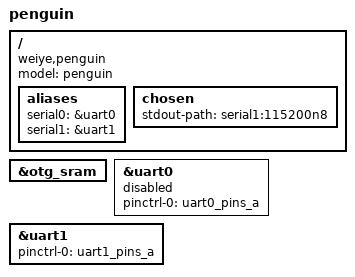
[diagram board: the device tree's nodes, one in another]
// SPDX-License-Identifier: (GPL-2.0+ OR X11)
/*
 * Copyright 2022 Weiye Wang <wwytxjy@163.com>
 */

/dts-v1/;
#include "suniv-f1c100s.dtsi"

#include <dt-bindings/gpio/gpio.h>

/ {
	model = "penguin";
	compatible = "weiye,penguin", "allwinner,suniv-f1c100s",
		     "allwinner,suniv";

	aliases {
		serial0 = &uart0;
		serial1 = &uart1;
	};

	chosen {
		stdout-path = "serial1:115200n8";
	};
};

&otg_sram {
	status = "okay";
};

&uart0 {
	pinctrl-names = "default";
	pinctrl-0 = <&uart0_pins_a>;
	status = "disabled";
};

&uart1 {
	pinctrl-names = "default";
	pinctrl-0 = <&uart1_pins_a>;
	status = "okay";
};
